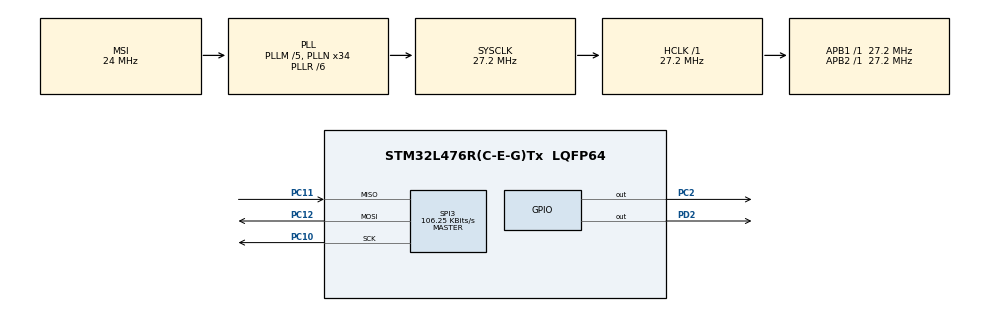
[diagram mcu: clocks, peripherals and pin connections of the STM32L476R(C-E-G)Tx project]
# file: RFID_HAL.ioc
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Mcu.Family=STM32L4
Mcu.Name=STM32L476R(C-E-G)Tx
Mcu.Package=LQFP64
NVIC.PriorityGroup=NVIC_PRIORITYGROUP_4
PC10.Mode=Full_Duplex_Master
PC10.Signal=SPI3_SCK
PC11.Mode=Full_Duplex_Master
PC11.Signal=SPI3_MISO
PC12.Mode=Full_Duplex_Master
PC12.Signal=SPI3_MOSI
PC14-OSC32_IN\ (PC14).Mode=LSE-External-Oscillator
PC14-OSC32_IN\ (PC14).Signal=RCC_OSC32_IN
PC15-OSC32_OUT\ (PC15).Mode=LSE-External-Oscillator
PC15-OSC32_OUT\ (PC15).Signal=RCC_OSC32_OUT
PC2.GPIO_Speed=GPIO_SPEED_FREQ_VERY_HIGH
PC2.Signal=GPIO_Output
PD2.GPIO_Speed=GPIO_SPEED_FREQ_VERY_HIGH
PD2.PinState=GPIO_PIN_SET
PD2.Signal=GPIO_Output
ProjectManager.HeapSize=0x200
ProjectManager.StackSize=0x400
ProjectManager.TargetToolchain=MDK-ARM V5.32
RCC.ADCFreq_Value=19200000
RCC.AHBFreq_Value=27200000
RCC.APB1Freq_Value=27200000
RCC.APB1TimFreq_Value=27200000
RCC.APB2Freq_Value=27200000
RCC.APB2TimFreq_Value=27200000
RCC.CortexFreq_Value=27200000
RCC.HCLKFreq_Value=27200000
RCC.HSE_VALUE=8000000
RCC.HSI_VALUE=16000000
RCC.MSIClockRange=RCC_MSIRANGE_9
RCC.MSI_VALUE=24000000
RCC.PLLM=5
RCC.PLLN=34
RCC.PLLR=RCC_PLLR_DIV6
RCC.PREFETCH_ENABLE=1
RCC.SYSCLKFreq_VALUE=27200000
RCC.SYSCLKSource=RCC_SYSCLKSOURCE_PLLCLK
RCC.USBFreq_Value=19200000
RCC.VCOOutputFreq_Value=163200000
SPI3.BaudRatePrescaler=SPI_BAUDRATEPRESCALER_256
SPI3.CalculateBaudRate=106.25 KBits/s
SPI3.DataSize=SPI_DATASIZE_8BIT
SPI3.Direction=SPI_DIRECTION_2LINES
SPI3.Mode=SPI_MODE_MASTER
SPI3.VirtualType=VM_MASTER
board=NUCLEO-L476RG

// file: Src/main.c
/* USER CODE BEGIN Header */
/**
  ******************************************************************************
  * @file           : main.c
  * @brief          : Main program body
  ******************************************************************************
  * @attention
  *
  * Copyright (c) 2024 STMicroelectronics.
  * All rights reserved.
  *
  * This software is licensed under terms that can be found in the LICENSE file
  * in the root directory of this software component.
  * If no LICENSE file comes with this software, it is provided AS-IS.
  *
  ******************************************************************************
  */
/* USER CODE END Header */
#include "main.h"

/* USER CODE BEGIN Includes */
#include "rc522.h"
#include "string.h"
/* USER CODE END Includes */

SPI_HandleTypeDef hspi3;

/* USER CODE BEGIN PV */
uint8_t status;
uint8_t str[MAX_LEN]; // Max_LEN = 16
uint8_t sNum[5];
uint8_t card;
/* USER CODE END PV */

void SystemClock_Config(void);
static void MX_GPIO_Init(void);
static void MX_SPI3_Init(void);

int main(void)
{

  /* MCU Configuration--------------------------------------------------------*/

  /* Reset of all peripherals, Initializes the Flash interface and the Systick. */
  HAL_Init();

  /* Configure the system clock */
  SystemClock_Config();

  /* Initialize all configured peripherals */
  MX_GPIO_Init();
  MX_SPI3_Init();
  /* USER CODE BEGIN 2 */
	MFRC522_Init();
  /* USER CODE END 2 */

  /* Infinite loop */
  while (1)
  {
		status = MFRC522_Request(PICC_REQIDL, str);
		status = MFRC522_Anticoll(str);
		memcpy(sNum, str, 5);
		HAL_Delay(100);

		if((str[0]==113) && (str[1]==223) && (str[2]==49) && (str[3]==2) && (str[4]==157) )
    {
			//HAL_GPIO_WritePin(GPIOC,GPIO_PIN_13,0);
			card = 1;
			HAL_Delay(100);
    }
    else if((str[0]==115) && (str[1]==233) && (str[2]==59) && (str[3]==218) && (str[4]==123) )
    {
      //HAL_GPIO_WritePin(GPIOC,GPIO_PIN_13,0);
			card = 2;
      HAL_Delay(2000);
    }
    else
    {
      card = 3;
    }

  }
}

void SystemClock_Config(void)
{
  RCC_OscInitTypeDef RCC_OscInitStruct = {0};
  RCC_ClkInitTypeDef RCC_ClkInitStruct = {0};

  /** Configure the main internal regulator output voltage
  */
  if (HAL_PWREx_ControlVoltageScaling(PWR_REGULATOR_VOLTAGE_SCALE1) != HAL_OK)
  {
    Error_Handler();
  }

  /** Configure LSE Drive Capability
  */
  HAL_PWR_EnableBkUpAccess();
  __HAL_RCC_LSEDRIVE_CONFIG(RCC_LSEDRIVE_LOW);

  /** Initializes the RCC Oscillators according to the specified parameters
  * in the RCC_OscInitTypeDef structure.
  */
  RCC_OscInitStruct.OscillatorType = RCC_OSCILLATORTYPE_LSE|RCC_OSCILLATORTYPE_MSI;
  RCC_OscInitStruct.LSEState = RCC_LSE_ON;
  RCC_OscInitStruct.MSIState = RCC_MSI_ON;
  RCC_OscInitStruct.MSICalibrationValue = 0;
  RCC_OscInitStruct.MSIClockRange = RCC_MSIRANGE_9;
  RCC_OscInitStruct.PLL.PLLState = RCC_PLL_ON;
  RCC_OscInitStruct.PLL.PLLSource = RCC_PLLSOURCE_MSI;
  RCC_OscInitStruct.PLL.PLLM = 5;
  RCC_OscInitStruct.PLL.PLLN = 34;
  RCC_OscInitStruct.PLL.PLLP = RCC_PLLP_DIV7;
  RCC_OscInitStruct.PLL.PLLQ = RCC_PLLQ_DIV2;
  RCC_OscInitStruct.PLL.PLLR = RCC_PLLR_DIV6;
  if (HAL_RCC_OscConfig(&RCC_OscInitStruct) != HAL_OK)
  {
    Error_Handler();
  }

  /** Initializes the CPU, AHB and APB buses clocks
  */
  RCC_ClkInitStruct.ClockType = RCC_CLOCKTYPE_HCLK|RCC_CLOCKTYPE_SYSCLK
                              |RCC_CLOCKTYPE_PCLK1|RCC_CLOCKTYPE_PCLK2;
  RCC_ClkInitStruct.SYSCLKSource = RCC_SYSCLKSOURCE_PLLCLK;
  RCC_ClkInitStruct.AHBCLKDivider = RCC_SYSCLK_DIV1;
  RCC_ClkInitStruct.APB1CLKDivider = RCC_HCLK_DIV1;
  RCC_ClkInitStruct.APB2CLKDivider = RCC_HCLK_DIV1;

  if (HAL_RCC_ClockConfig(&RCC_ClkInitStruct, FLASH_LATENCY_1) != HAL_OK)
  {
    Error_Handler();
  }

  /** Enable MSI Auto calibration
  */
  HAL_RCCEx_EnableMSIPLLMode();
}

static void MX_SPI3_Init(void)
{

  /* SPI3 parameter configuration*/
  hspi3.Instance = SPI3;
  hspi3.Init.Mode = SPI_MODE_MASTER;
  hspi3.Init.Direction = SPI_DIRECTION_2LINES;
  hspi3.Init.DataSize = SPI_DATASIZE_8BIT;
  hspi3.Init.CLKPolarity = SPI_POLARITY_LOW;
  hspi3.Init.CLKPhase = SPI_PHASE_1EDGE;
  hspi3.Init.NSS = SPI_NSS_SOFT;
  hspi3.Init.BaudRatePrescaler = SPI_BAUDRATEPRESCALER_256;
  hspi3.Init.FirstBit = SPI_FIRSTBIT_MSB;
  hspi3.Init.TIMode = SPI_TIMODE_DISABLE;
  hspi3.Init.CRCCalculation = SPI_CRCCALCULATION_DISABLE;
  hspi3.Init.CRCPolynomial = 7;
  hspi3.Init.CRCLength = SPI_CRC_LENGTH_DATASIZE;
  hspi3.Init.NSSPMode = SPI_NSS_PULSE_ENABLE;
  if (HAL_SPI_Init(&hspi3) != HAL_OK)
  {
    Error_Handler();
  }

}

static void MX_GPIO_Init(void)
{
  GPIO_InitTypeDef GPIO_InitStruct = {0};

  /* GPIO Ports Clock Enable */
  __HAL_RCC_GPIOC_CLK_ENABLE();
  __HAL_RCC_GPIOD_CLK_ENABLE();

  /*Configure GPIO pin Output Level */
  HAL_GPIO_WritePin(GPIOC, GPIO_PIN_2, GPIO_PIN_RESET);

  /*Configure GPIO pin Output Level */
  HAL_GPIO_WritePin(GPIOD, GPIO_PIN_2, GPIO_PIN_SET);

  /*Configure GPIO pin : PC2 */
  GPIO_InitStruct.Pin = GPIO_PIN_2;
  GPIO_InitStruct.Mode = GPIO_MODE_OUTPUT_PP;
  GPIO_InitStruct.Pull = GPIO_NOPULL;
  GPIO_InitStruct.Speed = GPIO_SPEED_FREQ_VERY_HIGH;
  HAL_GPIO_Init(GPIOC, &GPIO_InitStruct);

  /*Configure GPIO pin : PD2 */
  GPIO_InitStruct.Pin = GPIO_PIN_2;
  GPIO_InitStruct.Mode = GPIO_MODE_OUTPUT_PP;
  GPIO_InitStruct.Pull = GPIO_NOPULL;
  GPIO_InitStruct.Speed = GPIO_SPEED_FREQ_VERY_HIGH;
  HAL_GPIO_Init(GPIOD, &GPIO_InitStruct);

}

void Error_Handler(void)
{
  __disable_irq();
  while (1)
  {
  }
}
